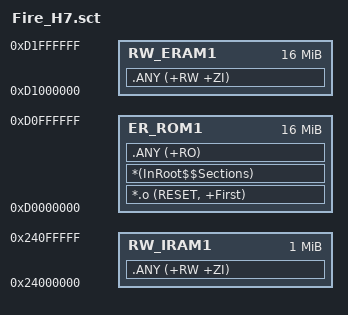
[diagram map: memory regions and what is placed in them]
; *************************************************************
; *** Scatter-Loading Description File generated by uVision ***
; *************************************************************

LR_ROM1 0xD0000000 0x01000000  {    ; load region size_region
  ER_ROM1 0xD0000000 0x01000000  {  ; load address = execution address
  *.o (RESET, +First)
   *(InRoot$$Sections)
   .ANY (+RO)
  }
  RW_IRAM1 0x24000000 0x00100000  {  ; RW data
   .ANY (+RW +ZI)
  }
  
   RW_ERAM1 0xD1000000 0x01000000  {  ; RW data
   .ANY (+RW +ZI)
  }
}


